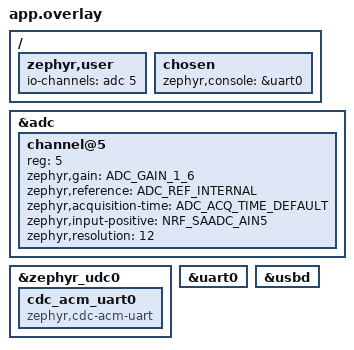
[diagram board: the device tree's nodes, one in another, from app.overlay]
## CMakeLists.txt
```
# SPDX-License-Identifier: Apache-2.0

cmake_minimum_required(VERSION 3.20.0)
find_package(Zephyr REQUIRED HINTS $ENV{ZEPHYR_BASE})
project(cdc_acm)

FILE(GLOB app_sources src/*.c)
target_sources(app PRIVATE
  src/main.c
  src/kprint.c
  src/my_service.c
)
```

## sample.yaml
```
sample:
  name: CDC ACM USB
tests:
  sample.usb.cdc-acm:
    depends_on: usb_device
    tags: usb
    platform_exclude: native_posix native_posix_64
    harness: console
    harness_config:
      type: one_line
      regex:
        - "Wait for DTR"
  sample.usb_device_next.cdc-acm:
    depends_on: usb_device
    tags: usb
    extra_args: CONF_FILE="usbd_next_prj.conf"
    platform_allow: nrf52840dk_nrf52840 frdm_k64f
    harness: console
    harness_config:
      type: one_line
      regex:
        - "Wait for DTR"
  sample.usb.cdc-acm.comp:
    depends_on: usb_device
    tags: usb
    platform_exclude: native_posix native_posix_64
    extra_args: OVERLAY_CONFIG=overlay-composite-cdc-msc.conf
    harness: console
    harness_config:
      type: one_line
      regex:
        - "Wait for DTR"
  sample.usb.cdc-acm.buildonly:
    depends_on: usb_device
    tags: usb
    platform_allow: native_posix native_posix_64
    build_only: true
    integration_platforms:
      - native_posix
```

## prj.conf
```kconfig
CONFIG_STDOUT_CONSOLE=y
CONFIG_USB_DEVICE_STACK=y
CONFIG_USB_DEVICE_PRODUCT="BLE Throttle Peripheral"
# Increased stack due to settings API usage
# CONFIG_SYSTEM_WORKQUEUE_STACK_SIZE=2048

CONFIG_BT=y
# CONFIG_BT_DEBUG_LOG=y
CONFIG_BT_SMP=y
CONFIG_BT_SIGNING=y
CONFIG_BT_PERIPHERAL=y
CONFIG_BT_DIS=y
CONFIG_BT_ATT_PREPARE_COUNT=5
CONFIG_BT_BAS=y
CONFIG_BT_HRS=y
CONFIG_BT_IAS=y
CONFIG_BT_PRIVACY=y
CONFIG_BT_DEVICE_NAME="BLE Throttle Transmitter V_01"
CONFIG_BT_DEVICE_APPEARANCE=833
CONFIG_BT_DEVICE_NAME_DYNAMIC=y
CONFIG_BT_DEVICE_NAME_MAX=65
CONFIG_BT_DIS_MODEL="nRF52840_Acclient"
CONFIG_BT_DIS_MANUF="Br1Ge9se"
CONFIG_BT_KEYS_OVERWRITE_OLDEST=y
CONFIG_BT_SETTINGS=n
CONFIG_FLASH=y
CONFIG_FLASH_PAGE_LAYOUT=y
CONFIG_FLASH_MAP=y
CONFIG_NVS=y
CONFIG_SETTINGS=y
CONFIG_BT_DIS_SERIAL_NUMBER=y
CONFIG_BT_DIS_SERIAL_NUMBER_STR="000001"
CONFIG_ADC=y
CONFIG_DEBUG_THREAD_INFO=y
CONFIG_DEBUG_OPTIMIZATIONS=y
CONFIG_NRFX_SAADC=y
CONFIG_ADC_NRFX_SAADC=y
CONFIG_USB_DEVICE_PID=0x0001
# CONFIG_LOG=y
# CONFIG_USB_DRIVER_LOG_LEVEL_ERR=y
# CONFIG_USB_DEVICE_LOG_LEVEL_ERR=y
CONFIG_SERIAL=y
CONFIG_UART_INTERRUPT_DRIVEN=y
CONFIG_UART_LINE_CTRL=y
CONFIG_USB_DEVICE_INITIALIZE_AT_BOOT=n

CONFIG_DK_LIBRARY=y
```

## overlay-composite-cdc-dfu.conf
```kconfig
# Overlay file for composite configuration
# CDC ACM + USB DFU
#
# This composite configuration may not work for Windows OS Host.
# Windows OS does not send reset after DFU_DETACH request
# (does not re-enumerates) and thus make it unable for the device
# to restart in DFU mode.

CONFIG_USB_COMPOSITE_DEVICE=y

CONFIG_USB_DFU_CLASS=y
CONFIG_FLASH=y
CONFIG_IMG_MANAGER=y
CONFIG_FLASH_PAGE_LAYOUT=y
CONFIG_BOOTLOADER_MCUBOOT=y
```

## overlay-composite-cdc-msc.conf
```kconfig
# Overlay file for composite configuration
# CDC ACM + Mass Storage (RAM)

CONFIG_USB_COMPOSITE_DEVICE=y

CONFIG_USB_MASS_STORAGE=y
CONFIG_USB_MASS_STORAGE_LOG_LEVEL_ERR=y

#RAM DISK
CONFIG_DISK_DRIVER_RAM=y
```

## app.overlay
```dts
/*
 * Copyright (c) 2021 Nordic Semiconductor ASA
 *
 * SPDX-License-Identifier: Apache-2.0
 */

&adc {
	#address-cells = <1>;
	#size-cells = <0>;

	channel@5 {
		reg = <5>;
		zephyr,gain = "ADC_GAIN_1_6";
		zephyr,reference = "ADC_REF_INTERNAL";
		zephyr,acquisition-time = <ADC_ACQ_TIME_DEFAULT>;
		zephyr,input-positive = <NRF_SAADC_AIN5>; /* P0.03 */
		zephyr,resolution = <12>;
	};

};

&zephyr_udc0 {
	cdc_acm_uart0 {
		compatible = "zephyr,cdc-acm-uart";
	};
};

&uart0 {
    status = "okay";
};

&usbd {
    status = "okay";
};

/ {
    zephyr,user {
		io-channels = <&adc 5>;
	};
    
	chosen {
		/* zephyr,console = &usbd; */
		zephyr,console = &uart0;
	};
};
```

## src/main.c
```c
/*
 * Copyright (c) 2023 Br1Ge9se
 *
 * SPDX-License-Identifier: Apache-2.0
 */

/**
 * @file
 * @brief BT Throttle peripheral app
 *
 * App for transmitting the ADC potentiometer value to the BLE Central.
 * USB CDC ACM is used as a terminal console.
 *
 */

#include <stdio.h>
#include <stddef.h>
#include <string.h>
#include <zephyr/device.h>
#include <zephyr/drivers/uart.h>
#include <zephyr/sys/byteorder.h>
#include <zephyr/kernel.h>
#include <zephyr/sys/ring_buffer.h>
#include <zephyr/drivers/gpio.h>
#include <zephyr/usb/usb_device.h>
#include <zephyr/usb/usbd.h>
#include <dk_buttons_and_leds.h>
#include <soc.h>
#include <nrfx_saadc.h>
#include "saadc_examples_common.h"
#include "nrfx_example.h"
#include <zephyr/bluetooth/bluetooth.h>
#include <zephyr/bluetooth/hci.h>
#include <zephyr/bluetooth/conn.h>
#include <zephyr/bluetooth/uuid.h>
#include <zephyr/bluetooth/gatt.h>
#include <zephyr/sys/reboot.h>

#include "my_service.h"

/*****************************************************************************************
 *
 *
 *****************************************************************************************/
#define NUM_OF_LEDS 4
/* The devicetree node identifier for the "led0" alias. */
#define LED0_NODE DT_ALIAS(led0)
/* The devicetree node identifier for the "led1" alias. */
#define LED1_NODE DT_ALIAS(led1)
/* The devicetree node identifier for the "led2" alias. */
#define LED2_NODE DT_ALIAS(led2)
/* The devicetree node identifier for the "led3" alias. */
#define LED3_NODE DT_ALIAS(led3)

static const struct gpio_dt_spec led[NUM_OF_LEDS] = 
{
	GPIO_DT_SPEC_GET(LED0_NODE, gpios),
	GPIO_DT_SPEC_GET(LED1_NODE, gpios),
	GPIO_DT_SPEC_GET(LED2_NODE, gpios),
	GPIO_DT_SPEC_GET(LED3_NODE, gpios)
};


#define ANALOG_INPUT_A5 5

/** @brief Symbol specifying analog input to be observed by SAADC channel 5. */
#define CH5_AIN ANALOG_INPUT_TO_SAADC_AIN(ANALOG_INPUT_A5)

/**
 * Button to restart sys
 */
#define KEY_READVAL_MASK DK_BTN1_MSK

/** @brief Declaration of enum containing a set of states for the simple state machine. */
typedef enum
{
    STATE_SINGLE_CONFIG,     ///< Configure a single SAADC channel and set the SAADC driver in the simple mode.
    STATE_SINGLE_SAMPLING,   ///< Trigger SAADC sampling on the single channel.
} adc_state_t;

/** @brief SAADC channel configuration structure for channel use. */
static const nrfx_saadc_channel_t m_single_channel = NRFX_SAADC_DEFAULT_CHANNEL_SE(CH5_AIN, 0);

/** @brief Buffer to store channel's values. */
static nrf_saadc_value_t m_samples_buffer;

/** @brief Symbol specifying the number of SAADC samplings to trigger. */
#define SAMPLING_ITERATIONS 256

/** @brief Enum with the current state of the simple state machine. */
static adc_state_t m_current_state = STATE_SINGLE_CONFIG;

/** @brief Flag indicating that sampling on every specified channel is finished and buffer ( @ref m_samples_buffer ) is filled with samples. */
static bool m_saadc_ready;

static uint32_t saadc_curr_value = 0;

#ifdef DONGLE
	static const struct device *console_dev = NULL;

	extern void zprintf(const char *fmt, ...);
	extern void zprint_init(const struct device *dev);
#else
	#define zprintf printk
#endif

#define DEVICE_NAME             CONFIG_BT_DEVICE_NAME
#define DEVICE_NAME_LEN         (sizeof(DEVICE_NAME) - 1)

static K_SEM_DEFINE(ble_init_ok, 0, 1);

static const struct bt_data ad[] = 
{
	BT_DATA_BYTES(BT_DATA_FLAGS, (BT_LE_AD_GENERAL | BT_LE_AD_NO_BREDR)),
	BT_DATA(BT_DATA_NAME_COMPLETE, DEVICE_NAME, DEVICE_NAME_LEN),
};

static const struct bt_data sd[] = 
{
	BT_DATA_BYTES(BT_DATA_UUID128_ALL, MY_SERVICE_UUID),
};

struct bt_conn *my_connection;

// LOG_MODULE_REGISTER(cdc_acm_echo, LOG_LEVEL_INF);

#define RING_BUF_SIZE 1024
uint8_t ring_buffer[RING_BUF_SIZE];

struct ring_buf ringbuf;

uint8_t led2blk;

USBD_DEVICE_DEFINE(sample_usbd,
		   DEVICE_DT_GET(DT_NODELABEL(zephyr_udc0)),
		   0x2fe3, 0x0001);
/*****************************************************************************************
 *
 *
 *****************************************************************************************/

/**
 * @brief Key pressed handler
 *
 */
static void button_handler(uint32_t button_state, uint32_t has_changed)
{
	uint32_t button = button_state & has_changed;

	if (button & KEY_READVAL_MASK) {
		
		zprintf("!!! System restart !!!");
		k_sleep(K_MSEC(500));
		sys_reboot(SYS_REBOOT_WARM);
	}
}
/**
 * @brief Function for handling SAADC driver events.
 *
 * @param[in] p_event Pointer to an SAADC driver event.
 */
static void saadc_handler(nrfx_saadc_evt_t const * p_event)
{
    nrfx_err_t status;
    (void)status;
	
    switch (p_event->type)
    {
        case NRFX_SAADC_EVT_DONE:
 //           zprintf("[Sample %d] value == %d\n\r", cnt_conv++, p_event->data.done.p_buffer[0]);
            saadc_curr_value = p_event->data.done.p_buffer[0];
            m_saadc_ready = true;
            break;

        case NRFX_SAADC_EVT_CALIBRATEDONE:
            status = nrfx_saadc_mode_trigger();
            NRFX_ASSERT(status == NRFX_SUCCESS);
            break;

        default:
            break;
    }
}

/**
 * @brief Function for 
 *
 */
static void saadc_notify(void)
{
	uint32_t sampling_index = 0;
	nrfx_err_t status;

	switch (m_current_state)
	{
		case STATE_SINGLE_CONFIG:
			status = nrfx_saadc_channel_config(&m_single_channel);
			NRFX_ASSERT(status == NRFX_SUCCESS);

			uint32_t channels_mask = nrfx_saadc_channels_configured_get();
			status = nrfx_saadc_simple_mode_set(channels_mask,
												NRF_SAADC_RESOLUTION_8BIT,
												NRF_SAADC_OVERSAMPLE_8X,
												saadc_handler);
			NRFX_ASSERT(status == NRFX_SUCCESS);

			status = nrfx_saadc_buffer_set(&m_samples_buffer, 1);
			NRFX_ASSERT(status == NRFX_SUCCESS);

			m_saadc_ready = true;
			m_current_state = STATE_SINGLE_SAMPLING;
			break;

		case STATE_SINGLE_SAMPLING:
			if (m_saadc_ready && sampling_index < SAMPLING_ITERATIONS)
			{
				status = nrfx_saadc_mode_trigger();
				NRFX_ASSERT(status == NRFX_SUCCESS);
				m_saadc_ready = false;
				sampling_index++;
			}
			else if (m_saadc_ready && sampling_index == SAMPLING_ITERATIONS)
			{
				status = nrfx_saadc_offset_calibrate(saadc_handler);
				NRFX_ASSERT(status == NRFX_SUCCESS);
				m_saadc_ready = false;
				sampling_index = 0;
			}
			break;

		default:
			break;
	}
}

#ifdef DONGLE
/**
 * @brief Uart Interrupt Handler
 *
 * @param[in] 
 */
static void uart_interrupt_handler(const struct device *dev, void *user_data)
{
	ARG_UNUSED(user_data);

	while (uart_irq_update(dev) && uart_irq_is_pending(dev)) {
		if (uart_irq_rx_ready(dev)) {
			int recv_len, rb_len;
			uint8_t buffer[64];
			size_t len = MIN(ring_buf_space_get(&ringbuf),
					 sizeof(buffer));

			recv_len = uart_fifo_read(dev, buffer, len);
			if (recv_len < 0) {
//				LOG_ERR("Failed to read UART FIFO");
				zprintf("Failed to read UART FIFO\n");
				recv_len = 0;
			};

			rb_len = ring_buf_put(&ringbuf, buffer, recv_len);
			if (rb_len < recv_len) {
//				LOG_ERR("Drop %u bytes", recv_len - rb_len);
				zprintf("Drop %u bytes\n", recv_len - rb_len);
			}
		}
	}
}
#endif

/**
 * @brief Function for initialize LEDs.
 *
 */
static int init_leds(void) {
    int ret = 0;
    
    for (int i=0; i<NUM_OF_LEDS; i++)
	{
		ret = gpio_pin_configure_dt(&led[i], GPIO_OUTPUT_ACTIVE);
		if (ret < 0) {
//			zprintf("gpio configuration error\n");
			return ret;
		}
	}

    gpio_pin_set_dt(&led[0], 0);
    gpio_pin_set_dt(&led[1], 0);
    gpio_pin_set_dt(&led[2], 0);
    gpio_pin_set_dt(&led[3], 0);
    
    return ret;
}

#ifdef DONGLE
/**
 * @brief Function for starting console.
 *
 * @param[in] p_event Pointer to an SAADC driver event.
 */
static int start_console(void) {
    uint32_t baudrate, dtr = 0U;
	int ret;
    
    console_dev = DEVICE_DT_GET_ONE(zephyr_cdc_acm_uart);
	if (!device_is_ready(console_dev)) {
//		LOG_ERR("CDC ACM device not ready");
		zprintf("CDC ACM device not ready\n");
		return 1;
	}

	ret = usb_enable(NULL);
	if (ret != 0) {
//		LOG_ERR("Failed to enable USB");
		zprintf("Failed to enable USB\n");
		return ret;
	}

	ring_buf_init(&ringbuf, sizeof(ring_buffer), ring_buffer);

//	LOG_INF("Wait for DTR");
	zprintf("Wait for DTR\n");
    while (true) {
		uart_line_ctrl_get(console_dev, UART_LINE_CTRL_DTR, &dtr);
		if (dtr) {
			break;
		} else {
			/* Give CPU resources to low priority threads. */
			k_sleep(K_MSEC(100));
			break;	//??????????????????
		}
	}

//	LOG_INF("DTR set");
	zprintf("DTR set\n");

	/* They are optional, we use them to test the interrupt endpoint */
	ret = uart_line_ctrl_set(console_dev, UART_LINE_CTRL_DCD, 1);
	if (ret) {
//		LOG_WRN("Failed to set DCD, ret code %d", ret);
		zprintf("Failed to set DCD, ret code %d\n", ret);
	}

	ret = uart_line_ctrl_set(console_dev, UART_LINE_CTRL_DSR, 1);
	if (ret) {
//		LOG_WRN("Failed to set DSR, ret code %d", ret);
		zprintf("Failed to set DSR, ret code %d\n", ret);
	}

	/* Wait 1 sec for the host to do all settings */
	k_busy_wait(1000000);

	ret = uart_line_ctrl_get(console_dev, UART_LINE_CTRL_BAUD_RATE, &baudrate);
	if (ret) {
//		LOG_WRN("Failed to get baudrate, ret code %d", ret);
		zprintf("Failed to get baudrate, ret code %d\n", ret);
	} else {
//		LOG_INF("Baudrate detected: %d", baudrate);
		zprintf("Baudrate detected: %d\n", baudrate);
	}

	uart_irq_callback_set(console_dev, uart_interrupt_handler);

	/* Enable rx interrupts */
	uart_irq_rx_enable(console_dev);
    
    /* Init zprintf */
	zprint_init(console_dev);
    
    return ret;
}
#endif

/**
 * @brief BT connected callback
 *
 * @param[in] 
 */
static void connected(struct bt_conn *conn, u8_t err)
{
	struct bt_conn_info info; 
	char addr[BT_ADDR_LE_STR_LEN];

	my_connection = conn;

	if (err) 
	{
		zprintf("Connection failed (err %u)\n", err);
		return;
	}
	else if(bt_conn_get_info(conn, &info))
	{
		zprintf("Could not parse connection info\n");
	}
	else
	{
		bt_addr_le_to_str(bt_conn_get_dst(conn), addr, sizeof(addr));
		
		zprintf("Connection established!\n");
		zprintf("Connected to: %s						\n", addr);
		zprintf("Connection Interval: %u				\n", info.le.interval);
		zprintf("Slave Latency: %u						\n", info.le.latency);
		zprintf("Connection Supervisory Timeout: %u		\n", info.le.timeout);
	}
}

/**
 * @brief BT disconnected callback
 *
 * @param[in] 
 */
static void disconnected(struct bt_conn *conn, u8_t reason)
{
	zprintf("Disconnected (reason %u)\n", reason);
	my_connection = NULL;
}

/**
 * @brief BT param req callback
 *
 * @param[in] 
 */
static bool le_param_req(struct bt_conn *conn, struct bt_le_conn_param *param)
{
	//If acceptable params, return true, otherwise return false.
	return true; 
}

/**
 * @brief BT param updated callback
 *
 * @param[in] 
 */
static void le_param_updated(struct bt_conn *conn, u16_t interval, u16_t latency, u16_t timeout)
{
	struct bt_conn_info info; 
	char addr[BT_ADDR_LE_STR_LEN];
	
	if(bt_conn_get_info(conn, &info))
	{
		zprintf("Could not parse connection info\n");
	}
	else
	{
		bt_addr_le_to_str(bt_conn_get_dst(conn), addr, sizeof(addr));
		
		zprintf("Connection parameters updated!\n");
		zprintf("Connected to: %s						\n", addr);
		zprintf("New Connection Interval: %u			\n", info.le.interval);
		zprintf("New Slave Latency: %u					\n", info.le.latency);
		zprintf("New Connection Supervisory Timeout: %u	\n", info.le.timeout);
	}
}

/**
 * @brief BT callbacks struct
 *
 */
static struct bt_conn_cb conn_callbacks = 
{
	.connected				= connected,
	.disconnected   		= disconnected,
	.le_param_req			= le_param_req,
	.le_param_updated		= le_param_updated
};

/**
 * @brief BT ready callback
 *
 * @param[in] 
 */
static void bt_ready(int err)
{
	if (err) 
	{
		zprintf("BLE init failed with error code %d\n", err);
		return;
	}

	//Configure connection callbacks
	bt_conn_cb_register(&conn_callbacks);

	//Initalize services
	err = my_service_init();

	if (err) 
	{
		zprintf("Failed to init LBS (err:%d)\n", err);
		return;
	}

	//Start advertising
	err = bt_le_adv_start(BT_LE_ADV_CONN, ad, ARRAY_SIZE(ad),
			      sd, ARRAY_SIZE(sd));
	if (err) 
	{
		zprintf("Advertising failed to start (err %d)\n", err);
		return;
	}

	zprintf("Advertising successfully started\n");

	k_sem_give(&ble_init_ok);
}

/**
 * @brief Unrecoverable error 
 *
 */
static void error(void)
{
	gpio_pin_set_dt(&led[0], 0);
	gpio_pin_set_dt(&led[1], 0);
	gpio_pin_set_dt(&led[2], 1);
	while (true) {
		zprintf("Error!\n");
		/* Spin for ever */
		k_sleep(K_MSEC(1000)); //1000ms
	}
}

/**
 * @brief saadc initialization function
 *
 *
 */
static int init_saadc(void) {
    nrfx_err_t status;
    (void)status;

	status = nrfx_saadc_init(NRFX_SAADC_DEFAULT_CONFIG_IRQ_PRIORITY);
    if (status != NRFX_SUCCESS) {
		return -1;
    }
#if defined(__ZEPHYR__)
    IRQ_DIRECT_CONNECT(NRFX_IRQ_NUMBER_GET(NRF_SAADC), IRQ_PRIO_LOWEST, nrfx_saadc_irq_handler, 0);
#endif
    return 0;
}

/**
 * @brief Print out device info
 *
 *
 */
#define VERSION "  Version 0.1 (beta) - "

void vers(void)
{
	char s1[60]=VERSION, s2[]=__DATE__, s3[]=__TIME__;
	strcat(s1, s2);
	strcat(s1, " * ");
	strcat(s1, s3);
	zprintf("%s\n", s1);
}
static void prompt(void) {
	bt_addr_le_t my_addrs[3];
	size_t 	my_addrs_count;
	char dev[BT_ADDR_LE_STR_LEN];

	zprintf("\nDEVICE NAME  :        %s\n", CONFIG_BT_DEVICE_NAME);
	zprintf("MODEL        :        %s\n", CONFIG_BT_DIS_MODEL);
	zprintf("MANUFACTER   :        %s\n", CONFIG_BT_DIS_MANUF);
	zprintf("SERIAL NUMBER:        %s\n", CONFIG_BT_DIS_SERIAL_NUMBER_STR);
	vers();
	bt_id_get(NULL, &my_addrs_count);
	if (my_addrs_count>3) my_addrs_count = 3;
	bt_id_get(my_addrs, &my_addrs_count);
	for (size_t i=0; i<my_addrs_count; i++)
	{
		bt_addr_le_to_str(&my_addrs[i], dev, sizeof(dev));
		zprintf("ADDR (%d)     :        %s, type %u\n",
	       i+1, dev, my_addrs[i].type);
	}
	zprintf("\n");
}

/**
 * @brief main
 *
 *
 */
#define SIZEBUF 8
#define BT_SEND_PERIOD_MS 200
#define LED_BLINK_1_SEC (1000/BT_SEND_PERIOD_MS)
void main(void)
{
	int ret, rb_len, cnt;
    uint8_t buffer[SIZEBUF];

	my_connection = NULL;

    led2blk = 0;
    
	ret = init_leds();
    if (ret == 0) {
        led2blk |= 1;
    }
#ifdef DONGLE
    ret = start_console();
#endif
    if (ret == 0) {
        led2blk = 2;
    }

//    k_sleep(K_MSEC(5000));
    zprintf("\nUSB Console Init Code=%d\n\r", led2blk);
    cnt = 0;
    
    ret = init_saadc();
    if (ret) {
        zprintf("Saadc init failed\n");
        error(); //Catch error
    }

	ret = bt_enable(bt_ready);

	if (ret) 
	{
		zprintf("BLE initialization failed\n");
		error(); //Catch error
	}
		
	ret = dk_buttons_init(button_handler);
	if (ret) {
		zprintf("Failed to initialize buttons (err %d)\n", ret);
		error(); //Catch error
	}
    
    zprintf("********** Br1Ge9se BLE peripheral ADC **********\n");

	/* 	Bluetooth stack should be ready in less than 100 msec. 								\
																							\
		We use this semaphore to wait for bt_enable to call bt_ready before we proceed 		\
		to the main loop. By using the semaphore to block execution we allow the RTOS to 	\
		execute other tasks while we wait. */	
	ret = k_sem_take(&ble_init_ok, K_MSEC(500));

	if (!ret) 
	{
		zprintf("Bluetooth initialized\n");
	} else 
	{
		zprintf("BLE initialization did not complete in time\n");
		error(); //Catch error
	}

	ret = my_service_init();
    
	while(true) {
		k_sleep(K_MSEC(BT_SEND_PERIOD_MS));
        if (++cnt == LED_BLINK_1_SEC) {
            gpio_pin_toggle_dt(&led[led2blk]);
            cnt = 0;
        }

		saadc_notify();

		if (my_connection != NULL) {
			my_service_send(my_connection, (uint8_t *)&saadc_curr_value, sizeof(saadc_curr_value));
			gpio_pin_set_dt(&led[0], 1);
		}
		else {
			gpio_pin_set_dt(&led[0], 0);
		}
        rb_len = ring_buf_get(&ringbuf, buffer, sizeof(buffer));
        if (rb_len > 0) {
            buffer[rb_len] = 0;
			if (buffer[0] == '.') {
				prompt();
			}
			else {
				zprintf("%s", buffer);
				if (buffer[0] == '\r')
					zprintf("\n");
			}
        }
	}
}
```

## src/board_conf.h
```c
#ifndef BOARD_CONF_H
#define BOARD_CONF_H

#define DONGLE
//#undef DONGLE

#endif
```

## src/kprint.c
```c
/*
 * Copyright (c) 2010, 2013-2014 Wind River Systems, Inc.
 *
 * SPDX-License-Identifier: Apache-2.0
 */

/**
 * @file
 * @brief Low-level debug output
 *
 * Low-level debugging output. Platform installs a character output routine at
 * init time. If no routine is installed, a nop routine is called.
 */

#include <zephyr/kernel.h>
#include <stdarg.h>
#include <stdio.h>
#include <sys/types.h>
#include <zephyr/drivers/uart.h>
#include "board_conf.h"

#ifdef DONGLE
#define CFG_PBSIZE 128

static const struct device *dev = NULL;

void zprint_init(const struct device *mydev)
{
    dev = mydev;
}

/**
 * @brief Default character output routine
 * @param c Character to swallow
 *
 */

static void zputc(int c)
{
	uart_poll_out(dev, c);
}

void console_putc(char c)
{
    if (dev != NULL)
        zputc(c);
}

static int console_puts(const char *str)
{
	int n = 0;

	while (*str) {
		if (*str == '\n')
			console_putc('\r');

		console_putc(*str);
		str++;
		n++;
	}

	return n;
}

int zprintf(const char *fmt, ...)
{
	va_list args;
	unsigned int i;
	char printbuffer[CFG_PBSIZE];

	va_start(args, fmt);
	i = vsprintf(printbuffer, fmt, args);
	va_end(args);

	console_puts(printbuffer);

	return i;
}
#endif /* DONGLE */
```

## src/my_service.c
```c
#include <zephyr/types.h>
#include <stddef.h>
#include <string.h>
#include <errno.h>

#include <zephyr/sys/byteorder.h>
//#include <zephyr.h>
#include <soc.h>

#include <zephyr/bluetooth/bluetooth.h>
#include <zephyr/bluetooth/hci.h>
#include <zephyr/bluetooth/conn.h>
#include <zephyr/bluetooth/uuid.h>
#include <zephyr/bluetooth/addr.h>
#include <zephyr/bluetooth/gatt.h>

#include "my_service.h"

#define BT_UUID_MY_SERVICE      BT_UUID_DECLARE_128(MY_SERVICE_UUID)
#define BT_UUID_MY_SERVICE_RX   BT_UUID_DECLARE_128(RX_CHARACTERISTIC_UUID)
#define BT_UUID_MY_SERVICE_TX   BT_UUID_DECLARE_128(TX_CHARACTERISTIC_UUID)

#define MAX_TRANSMIT_SIZE 240//TODO figure this out

u8_t data_rx[MAX_TRANSMIT_SIZE];
u8_t data_tx[MAX_TRANSMIT_SIZE];

//extern void zprintf(const char *fmt, ...);

static bool warning_msg = false;

int my_service_init(void)
{
    int err = 0;

    memset(&data_rx, 0, MAX_TRANSMIT_SIZE);
    memset(&data_tx, 0, MAX_TRANSMIT_SIZE);

    return err;
}

/* This function is called whenever the RX Characteristic has been written to by a Client */
static ssize_t on_receive(struct bt_conn *conn,
			  const struct bt_gatt_attr *attr,
			  const void *buf,
			  u16_t len,
			  u16_t offset,
			  u8_t flags)
{
//    const u8_t * buffer = buf;
    /*
	zprintf("Received data, handle %d, conn %p, data: 0x", attr->handle, conn);
    for(u8_t i = 0; i < len; i++){
        zprintf("%02X", buffer[i]);
    }
    zprintf("\n");
    */
	return len;
}

/* This function is called whenever a Notification has been sent by the TX Characteristic */
static void on_sent(struct bt_conn *conn, void *user_data)
{
	ARG_UNUSED(user_data);

    //const bt_addr_le_t * addr = bt_conn_get_dst(conn);
    /*
	zprintf("Data sent to Address 0x %02X %02X %02X %02X %02X %02X \n", addr->a.val[0]
                                                                    , addr->a.val[1]
                                                                    , addr->a.val[2]
                                                                    , addr->a.val[3]
                                                                    , addr->a.val[4]
                                                                    , addr->a.val[5]);
    */
}

/* This function is called whenever the CCCD register has been changed by the client*/
void on_cccd_changed(const struct bt_gatt_attr *attr, u16_t value)
{
    ARG_UNUSED(attr);
    switch(value)
    {
        case BT_GATT_CCC_NOTIFY: 
            // Start sending stuff!
            break;

        case BT_GATT_CCC_INDICATE: 
            // Start sending stuff via indications
            break;

        case 0: 
            // Stop sending stuff
            break;
        
        default: 
            zprintf("Error, CCCD has been set to an invalid value");     
    }
}
                        

/* LED Button Service Declaration and Registration */
BT_GATT_SERVICE_DEFINE(my_service,
BT_GATT_PRIMARY_SERVICE(BT_UUID_MY_SERVICE),
BT_GATT_CHARACTERISTIC(BT_UUID_MY_SERVICE_RX,
			       BT_GATT_CHRC_WRITE | BT_GATT_CHRC_WRITE_WITHOUT_RESP,
			       BT_GATT_PERM_READ | BT_GATT_PERM_WRITE, 
                   NULL, on_receive, NULL),
BT_GATT_CHARACTERISTIC(BT_UUID_MY_SERVICE_TX,
			       BT_GATT_CHRC_NOTIFY,
			       BT_GATT_PERM_READ,
                   NULL, NULL, NULL),
BT_GATT_CCC(on_cccd_changed,
        BT_GATT_PERM_READ | BT_GATT_PERM_WRITE),
);

/* This function sends a notification to a Client with the provided data,
given that the Client Characteristic Control Descripter has been set to Notify (0x1).
It also calls the on_sent() callback if successful*/
void my_service_send(struct bt_conn *conn, const u8_t *data, uint16_t len)
{
    /* 
    The attribute for the TX characteristic is used with bt_gatt_is_subscribed 
    to check whether notification has been enabled by the peer or not.
    Attribute table: 0 = Service, 1 = Primary service, 2 = RX, 3 = TX, 4 = CCC.
    */
    const struct bt_gatt_attr *attr = &my_service.attrs[3]; 

    struct bt_gatt_notify_params params = 
    {
        .uuid   = BT_UUID_MY_SERVICE_TX,
        .attr   = attr,
        .data   = data,
        .len    = len,
        .func   = on_sent
    };

    // Check whether notifications are enabled or not
    if(bt_gatt_is_subscribed(conn, attr, BT_GATT_CCC_NOTIFY)) 
    {
        // Send the notification
	    if(bt_gatt_notify_cb(conn, &params))
        {
            zprintf("Error, unable to send notification\n");
        }
        warning_msg = false;
    }
    else if (!warning_msg)
    {
        zprintf("Warning, notification not enabled on the selected attribute\n");
        warning_msg = true;
    }
}
```

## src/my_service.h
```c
#include <zephyr/types.h>
#include <stddef.h>
#include <string.h>
#include <errno.h>
#include "board_conf.h"
#include <soc.h>

#include <zephyr/bluetooth/bluetooth.h>
#include <zephyr/bluetooth/hci.h>
#include <zephyr/bluetooth/conn.h>
#include <zephyr/bluetooth/uuid.h>
#include <zephyr/bluetooth/gatt.h>

#define MY_SERVICE_UUID 0xd4, 0x86, 0x48, 0x24, 0x54, 0xB3, 0x43, 0xA1, \
			            0xBC, 0x20, 0x97, 0x8F, 0xC3, 0x76, 0xC2, 0x75

#define RX_CHARACTERISTIC_UUID  0xA6, 0xE8, 0xC4, 0x60, 0x7E, 0xAA, 0x41, 0x6B, \
			                    0x95, 0xD4, 0x9D, 0xCC, 0x08, 0x4F, 0xCF, 0x6A

#define TX_CHARACTERISTIC_UUID  0xED, 0xAA, 0x20, 0x11, 0x92, 0xE7, 0x43, 0x5A, \
			                    0xAA, 0xE9, 0x94, 0x43, 0x35, 0x6A, 0xD4, 0xD3


#define u8_t uint8_t
#define u16_t uint16_t
#define u32_t uint32_t

#ifdef DONGLE
	extern void zprintf(const char *fmt, ...);
#else
	#define zprintf printk
#endif

/** @brief Callback type for when new data is received. */
typedef void (*data_rx_cb_t)(uint8_t *data, uint8_t length);

/** @brief Callback struct used by the my_service Service. */
struct my_service_cb 
{
	/** Data received callback. */
	data_rx_cb_t    data_rx_cb;
};

int my_service_init(void);

void my_service_send(struct bt_conn *conn, const uint8_t *data, uint16_t len);
```

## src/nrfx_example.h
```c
/*
 * Copyright (c) 2022, Nordic Semiconductor ASA
 * All rights reserved.
 *
 * SPDX-License-Identifier: BSD-3-Clause
 *
 * Redistribution and use in source and binary forms, with or without
 * modification, are permitted provided that the following conditions are met:
 *
 * 1. Redistributions of source code must retain the above copyright notice, this
 *    list of conditions and the following disclaimer.
 *
 * 2. Redistributions in binary form must reproduce the above copyright
 *    notice, this list of conditions and the following disclaimer in the
 *    documentation and/or other materials provided with the distribution.
 *
 * 3. Neither the name of the copyright holder nor the names of its
 *    contributors may be used to endorse or promote products derived from this
 *    software without specific prior written permission.
 *
 * THIS SOFTWARE IS PROVIDED BY THE COPYRIGHT HOLDERS AND CONTRIBUTORS "AS IS"
 * AND ANY EXPRESS OR IMPLIED WARRANTIES, INCLUDING, BUT NOT LIMITED TO, THE
 * IMPLIED WARRANTIES OF MERCHANTABILITY AND FITNESS FOR A PARTICULAR PURPOSE
 * ARE DISCLAIMED. IN NO EVENT SHALL THE COPYRIGHT HOLDER OR CONTRIBUTORS BE
 * LIABLE FOR ANY DIRECT, INDIRECT, INCIDENTAL, SPECIAL, EXEMPLARY, OR
 * CONSEQUENTIAL DAMAGES (INCLUDING, BUT NOT LIMITED TO, PROCUREMENT OF
 * SUBSTITUTE GOODS OR SERVICES; LOSS OF USE, DATA, OR PROFITS; OR BUSINESS
 * INTERRUPTION) HOWEVER CAUSED AND ON ANY THEORY OF LIABILITY, WHETHER IN
 * CONTRACT, STRICT LIABILITY, OR TORT (INCLUDING NEGLIGENCE OR OTHERWISE)
 * ARISING IN ANY WAY OUT OF THE USE OF THIS SOFTWARE, EVEN IF ADVISED OF THE
 * POSSIBILITY OF SUCH DAMAGE.
 */

#ifndef NRFX_EXAMPLE_H__
#define NRFX_EXAMPLE_H__

#if defined(__ZEPHYR__)
#include <zephyr/logging/log_ctrl.h>
#define NRFX_EXAMPLE_LOG_INIT()    LOG_INIT()
#define NRFX_EXAMPLE_LOG_PROCESS() while (LOG_PROCESS())
#else
#define NRFX_EXAMPLE_LOG_INIT()
#define NRFX_EXAMPLE_LOG_PROCESS()
#endif

#if defined(NRF52_SERIES)
#define LOOPBACK_PIN_1A 3
#define LOOPBACK_PIN_1B 31
#define LOOPBACK_PIN_2A 4
#define LOOPBACK_PIN_2B 30
#define LOOPBACK_PIN_3A 28
#define LOOPBACK_PIN_3B 29
#define LOOPBACK_PIN_4A 26
#define LOOPBACK_PIN_4B 27
#define ANALOG_INPUT_A0 1
#define ANALOG_INPUT_A1 2
#define ANALOG_INPUT_A2 4
#if defined(NRF52832_XXAA) || defined (NRF52832_XXAB)
#define LED1_PIN        17
#define LED2_PIN        18
#define LED3_PIN        19
#define LED4_PIN        20
#else
#define LED1_PIN        13
#define LED2_PIN        14
#define LED3_PIN        15
#define LED4_PIN        16
#endif
#elif defined(NRF53_SERIES)
#define LOOPBACK_PIN_1A 4
#define LOOPBACK_PIN_1B 26
#define LOOPBACK_PIN_2A 5
#define LOOPBACK_PIN_2B 25
#define LOOPBACK_PIN_3A 6
#define LOOPBACK_PIN_3B 7
#define LOOPBACK_PIN_4A 34
#define LOOPBACK_PIN_4B 35
#define ANALOG_INPUT_A0 0
#define ANALOG_INPUT_A1 1
#define ANALOG_INPUT_A2 2
#define LED1_PIN        28
#define LED2_PIN        29
#define LED3_PIN        30
#define LED4_PIN        31
#elif defined(NRF91_SERIES)
#define LOOPBACK_PIN_1A 14
#define LOOPBACK_PIN_1B 19
#define LOOPBACK_PIN_2A 15
#define LOOPBACK_PIN_2B 18
#define LOOPBACK_PIN_3A 16
#define LOOPBACK_PIN_3B 17
#define LOOPBACK_PIN_4A 30
#define LOOPBACK_PIN_4B 31
#define ANALOG_INPUT_A0 1
#define ANALOG_INPUT_A1 2
#define ANALOG_INPUT_A2 3
#define LED1_PIN        2
#define LED2_PIN        3
#define LED3_PIN        4
#define LED4_PIN        5
#else
#error "Unknown device."
#endif

#define ANALOG_INPUT_TO_SAADC_AIN(x) ((x) + 1)

#define ANALOG_INPUT_TO_COMP_AIN(x) (x)

#endif // NRFX_EXAMPLE_H__
```

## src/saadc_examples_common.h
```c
/*
 * Copyright (c) 2022, Nordic Semiconductor ASA
 * All rights reserved.
 *
 * SPDX-License-Identifier: BSD-3-Clause
 *
 * Redistribution and use in source and binary forms, with or without
 * modification, are permitted provided that the following conditions are met:
 *
 * 1. Redistributions of source code must retain the above copyright notice, this
 *    list of conditions and the following disclaimer.
 *
 * 2. Redistributions in binary form must reproduce the above copyright
 *    notice, this list of conditions and the following disclaimer in the
 *    documentation and/or other materials provided with the distribution.
 *
 * 3. Neither the name of the copyright holder nor the names of its
 *    contributors may be used to endorse or promote products derived from this
 *    software without specific prior written permission.
 *
 * THIS SOFTWARE IS PROVIDED BY THE COPYRIGHT HOLDERS AND CONTRIBUTORS "AS IS"
 * AND ANY EXPRESS OR IMPLIED WARRANTIES, INCLUDING, BUT NOT LIMITED TO, THE
 * IMPLIED WARRANTIES OF MERCHANTABILITY AND FITNESS FOR A PARTICULAR PURPOSE
 * ARE DISCLAIMED. IN NO EVENT SHALL THE COPYRIGHT HOLDER OR CONTRIBUTORS BE
 * LIABLE FOR ANY DIRECT, INDIRECT, INCIDENTAL, SPECIAL, EXEMPLARY, OR
 * CONSEQUENTIAL DAMAGES (INCLUDING, BUT NOT LIMITED TO, PROCUREMENT OF
 * SUBSTITUTE GOODS OR SERVICES; LOSS OF USE, DATA, OR PROFITS; OR BUSINESS
 * INTERRUPTION) HOWEVER CAUSED AND ON ANY THEORY OF LIABILITY, WHETHER IN
 * CONTRACT, STRICT LIABILITY, OR TORT (INCLUDING NEGLIGENCE OR OTHERWISE)
 * ARISING IN ANY WAY OUT OF THE USE OF THIS SOFTWARE, EVEN IF ADVISED OF THE
 * POSSIBILITY OF SUCH DAMAGE.
 */

#ifndef SAADC_EXAMPLES_COMMON_H__
#define SAADC_EXAMPLES_COMMON_H__

#include <nrfx_gpiote.h>

/**
 * @defgroup nrfx_saadc_examples_common Common SAADC module
 * @{
 * @ingroup nrfx_saadc_examples
 *
 * @brief Module with common functionalities used in nrfx_saadc examples.
 */

/**
 * @brief SAADC channel configuration for the single-ended mode with 3 us sample acquisition time.
 *        The 3 us acquisition time will work correctly when the source resistance of @p _pin_p input
 *        analog pin is less than 10 kOhm.
 *
 * This configuration sets up single-ended SAADC channel with the following options:
 * - resistor ladder disabled
 * - gain: 1/6
 * - reference voltage: internal 0.6 V
 * - sample acquisition time: 3 us
 * - burst disabled
 *
 * @param[in] _pin_p Positive input analog pin.
 * @param[in] _index Channel index.
 *
 * @sa nrfx_saadc_channel_t
 */
#define SAADC_CHANNEL_SE_ACQ_3US(_pin_p, _index)        \
{                                                       \
    .channel_config =                                   \
    {                                                   \
        .resistor_p = NRF_SAADC_RESISTOR_DISABLED,      \
        .resistor_n = NRF_SAADC_RESISTOR_DISABLED,      \
        .gain       = NRF_SAADC_GAIN1_6,                \
        .reference  = NRF_SAADC_REFERENCE_INTERNAL,     \
        .acq_time   = NRF_SAADC_ACQTIME_3US,            \
        .mode       = NRF_SAADC_MODE_SINGLE_ENDED,      \
        .burst      = NRF_SAADC_BURST_DISABLED,         \
    },                                                  \
    .pin_p          = (nrf_saadc_input_t)_pin_p,        \
    .pin_n          = NRF_SAADC_INPUT_DISABLED,         \
    .channel_index  = _index,                           \
}

/**
 * @brief Function for setting up a GPIOTE task that toggles a given pin.
 *
 * @param pin The pin to toggle.
 */
void gpiote_pin_toggle_task_setup(nrfx_gpiote_pin_t pin);

/**
 * @brief Function for setting up a pin to be toggled once specified event is triggered.
 *
 * @param pin The pin to toggle.
 * @param eep Address of the event register. This event will trigger the @p pin to toggle.
 */
void pin_on_event_toggle_setup(nrfx_gpiote_pin_t pin,
                               uint32_t          eep);

/** @} */

#endif // SAADC_EXAMPLES_COMMON_H__
```
